# HK32L0xx register map
Vendor: HKMicroChip Ltd.; Series: HK32L0xx; File version: 1.3
Arm 32-bit Cortex-M0 Microcontroller based device, CPU clock up to 48 MHz
CPU: CM0 r0p0, little endian, no MPU, no FPU, 3 interrupt priority bits
Registers are 32-bit, read-write, reset 0x0 unless marked. A register's access mark holds for its fields unless they carry their own. Offsets are from the block's base; lines under a group give offsets from that group; [hi:lo] are bit positions; {n}, {i} and the like mark numbered series; 'fields as' and 'values as' point back to an identical list; <NAME> marks a mode.

## Memory map
0x40000000 TIM2 size 0x400
0x40000400 TIM3 size 0x400
0x40002000 TIM14 size 0x400
0x40002400 LCD size 0x400
0x40002800 RTC size 0x400
0x40002C00 WWDG size 0x400
0x40003000 IWDG size 0x400
0x40003800 SPI2 size 0x400
0x40004000 LPUART size 0x400
0x40004400 USART2 size 0x400
0x40004800 UART3 size 0x400
0x40004C00 UART4 size 0x400
0x40005400 I2C1 size 0x400
0x40005800 I2C2 size 0x400
0x40005C00 USB size 0x400
0x40006400 CAN size 0x400
0x40006800 CLU size 0x400
0x40007000 PWR size 0x400
0x40007400 DAC size 0x400
0x40007C00 LPTIM1 size 0x400
0x40009400 LPTIM2 size 0x400
0x40010000 SYSCFG size 0x100
0x40010118 COMP1 size 0x4
0x4001011C COMP2 size 0x4
0x40010238 OPA1 size 0x4
0x4001023C OPA2 size 0x4
0x40010240 OPA3 size 0x4
0x40010400 EXTI size 0x400
0x40012000 BEEPER size 0x400
0x40012400 ADC size 0x400
0x40012C00 TIM1 size 0x400
0x40013000 SPI1 size 0x400
0x40013800 USART1 size 0x400
0x40014000 TIM15 size 0x400
0x40014400 TIM16 size 0x400
0x40014800 TIM17 size 0x400
0x40014C00 LPTIM3 size 0x400
0x40015800 DBGMCU size 0x400
0x40020000 DMA size 0x400
0x40020008 DMA_Channel1 size 0x14
0x4002001C DMA_Channel2 size 0x14
0x40020030 DMA_Channel3 size 0x14
0x40020044 DMA_Channel4 size 0x14
0x40020058 DMA_Channel5 size 0x14
0x4002006C DMA_Channel6 size 0x14
0x40020080 DMA_Channel7 size 0x14
0x40021000 RCC size 0x400
0x40022000 FLASH size 0x400
0x40023000 CRC size 0x400
0x40025000 TRNG size 0x400
0x40026000 AES size 0x400
0x40028000 EMACC size 0x400
0x40030000 DVSQ size 0x400
0x48000000 GPIOA size 0x400
0x48000400 GPIOB size 0x400
0x48000800 GPIOC size 0x400
0x48000C00 GPIOD size 0x400
0x48001400 GPIOF size 0x400

## Interrupts
0 WWDG — Window Watchdog interrupt
1 PVD (PWR) — PVD interrupt
2 RTC — RTC global interrupt
3 FLASH — Flash global interrupt
4 RCC — RCC global interrupt
5 EXTI0_1 (EXTI) — EXTI Line[1:0] interrupt
6 EXTI2_3 (EXTI) — EXTI Line[3:2] interrupt
7 EXTI4_15 (EXTI) — EXTI Line[15:4] interrupt
8 LPUART — LPUART interrupt
9 DMA_CH1 (DMA) — DMA Channel 1 global interrupt
10 DMA_CH2_3 (DMA) — DMA Channel 2/3 interrupt
11 DMA_CH4_7 (DMA) — DMA Channel4/5/6/7 interrupt
12 ADC_COMP1_2 (ADC) — ADC and Comparator1/2 interrupt
13 TIM1 — TIM1 global interrupt
14 UART3_4 (UART3) — UART3/4 global interrupt
15 TIM2 — TIM2 global interrupt
16 TIM3 — TIM3 global interrupt
17 DAC — DAC interrupt
18 LPTIM1_3 (LPTIM1) — LPTIM1/2/3 global interrupt
19 TIM14 — TIM14 global interrupt
20 TIM15 — TIM15 global interrupt
21 TIM16 — TIM16 global interrupt
22 TIM17 — TIM17 global interrupt
23 I2C1 — I2C1 global interrupt
24 I2C2 — I2C2 global interrupt
25 SPI1 — SPI1 global interrupt
26 SPI2 — SPI2 global interrupt
27 USART1 — USART1 global interrupt
28 USART2 — USART2 global interrupt
29 AES_TRNG_EMACC (AES) — AES/TRNG/ EMACC global interrupt
30 LCD_CAN (LCD) — LCD and CAN global interrupt
31 USB_DVSQ (USB) — USB and DVSQ global interrupt

## FLASH
Base 0x40022000
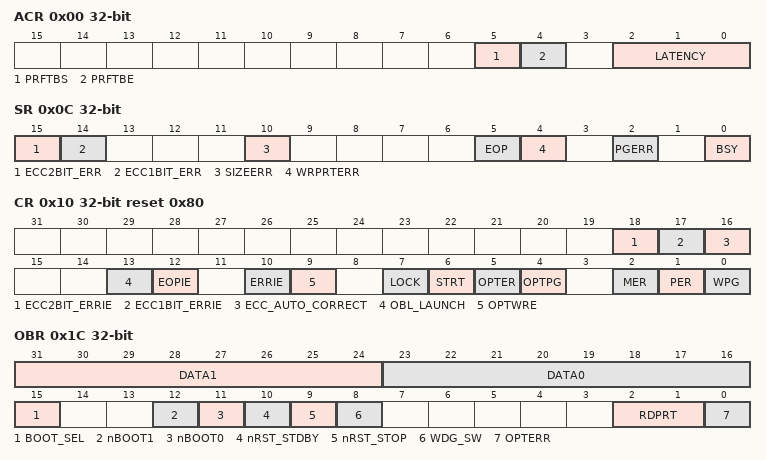
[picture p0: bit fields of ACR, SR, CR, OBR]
0x00 ACR access per field
  [5] PRFTBS ro — Prefetch buffer status
  [4] PRFTBE rw — Prefetch buffer enable
  [2:0] LATENCY rw
0x04 KEYR wo
  [31:0] FKEY — Flash key
0x08 OPTKEYR wo
  [31:0] OPTKEY — Option byte key
0x0C SR access per field
  [15] ECC2BIT_ERR rw — ECC detection 2-bit data error flag
  [14] ECC1BIT_ERR rw — ECC detection 1-bit data error flag
  [10] SIZEERR rw — Size error
  [5] EOP rw — End of operation
  [4] WRPRTERR rw — Write protection error
  [2] PGERR rw — Programming error
  [0] BSY ro — Busy
0x10 CR reset 0x80
  [18] ECC2BIT_ERRIE — ECC detection 2-bit data error interrupt enable
  [17] ECC1BIT_ERRIE — ECC detection 1-bit data error interrupt enable
  [16] ECC_AUTO_CORRECT — ECC automatic error correction
  [13] OBL_LAUNCH — Force option byte loading
  [12] EOPIE — End of operation interrupt enable
  [10] ERRIE — Error interrupt enable
  [9] OPTWRE — Option byte write enable
  [7] LOCK
  [6] STRT — Start
  [5] OPTER — Option byte erase
  [4] OPTPG — Option byte programming
  [2] MER — Mass erase
  [1] PER — Page erase
  [0] WPG — word programming
0x14 AR wo
  [31:0] FAR — Flash Address
0x1C OBR ro
  [31:24] DATA1 — User data
  [23:16] DATA0 — User data
  [15] BOOT_SEL — Boot Select
  [12] nBOOT1 — BOOT1 reverse bit
  [11] nBOOT0 — BOOT0 reverse bit
  [10] nRST_STDBY — Generate a reset when entering Standby mode
  [9] nRST_STOP — Generate a reset when entering Stop mode
  [8] WDG_SW — Hardware or software watchdog selection
  [2:1] RDPRT — Read protection level status
  [0] OPTERR — Option byte error
0x20 WRPR ro
  [31:0] WRP — Write protection
0x60 OBR2 ro
  [7:0] BOR_LEVEL — Brownout reset threshold level
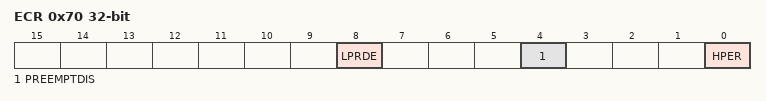
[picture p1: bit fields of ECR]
0x70 ECR
  [8] LPRDE — Low power read enable
  [4] PREEMPTDIS — Prefetch preemption
  [0] HPER — Half-page erase
0x78 ENCRY_CTL
  [0] ENCRY_EN — Encryption enable
0x7C DECRY_CTL
  [0] DECRY_EN — Decryption enable
0x80 UKEY1 wo
  [31:0] UKEY — Low 32 bits for Flash data encryption
0x84 UKEY2 wo
  [31:0] UKEY — High 32 bits for Flash data encryption
0x90 INT_VEC_OFFSET
  [14:0] INT_VEC_OFFSET — Interrupts vector offset

## Licence text in the file
HKMicroChip Limited (HKMicroChip) is supplying this software for use with Cortex-M0!
